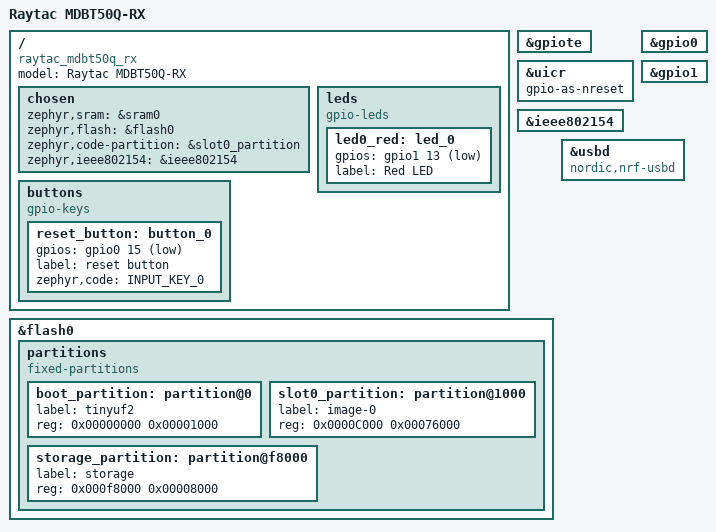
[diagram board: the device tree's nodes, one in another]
/*
 * Copyright (c) 2022 Nikola Trifunovic
 * Copyright (c) 2018 Nordic Semiconductor ASA
 * Copyright (c) 2017 Linaro Limited
 *
 * SPDX-License-Identifier: Apache-2.0
 */

/dts-v1/;
#include <nordic/nrf52840_qiaa.dtsi>
#include <zephyr/dt-bindings/input/input-event-codes.h>

/ {
	model = "Raytac MDBT50Q-RX";
	compatible = "raytac_mdbt50q_rx";

	chosen {
		zephyr,sram = &sram0;
		zephyr,flash = &flash0;
		zephyr,code-partition = &slot0_partition;
		zephyr,ieee802154 = &ieee802154;
	};

	leds {
		compatible = "gpio-leds";
		led0_red: led_0 {
			gpios = <&gpio1 13 GPIO_ACTIVE_LOW>;
			label = "Red LED";
		};
	};

	buttons {
		compatible = "gpio-keys";
		reset_button: button_0 {
			gpios = <&gpio0 15 (GPIO_PULL_UP | GPIO_ACTIVE_LOW)>;
			label = "reset button";
			zephyr,code = <INPUT_KEY_0>;
		};
	};
};

&gpiote {
	status = "okay";
};

&uicr {
	gpio-as-nreset;
};

&gpio0 {
	status = "okay";
};

&gpio1 {
	status = "okay";
};

&ieee802154 {
	status = "okay";
};

&flash0 {

	partitions {
		compatible = "fixed-partitions";
		#address-cells = <1>;
		#size-cells = <1>;

		boot_partition: partition@0 {
			label = "tinyuf2";
			reg = <0x00000000 0x00001000>;
		};
		slot0_partition: partition@1000 {
			label = "image-0";
			reg = <0x0000C000 0x00076000>;
		};

		/*
		 * The flash starting at 0x000f8000 and ending at
		 * 0x000fffff is reserved for use by the application.
		 */

		/*
		 * Storage partition will be used by FCB/LittleFS/NVS
		 * if enabled.
		 */
		storage_partition: partition@f8000 {
			label = "storage";
			reg = <0x000f8000 0x00008000>;
		};
	};
};

zephyr_udc0: &usbd {
	compatible = "nordic,nrf-usbd";
	status = "okay";
};
